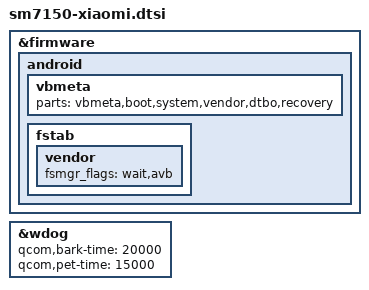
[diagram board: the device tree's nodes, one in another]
&firmware {
  android {
    vbmeta {
      parts = "vbmeta,boot,system,vendor,dtbo,recovery";
    };
    fstab {
      vendor {
          fsmgr_flags = "wait,avb";
      };
    };
  };
};

&wdog {
    qcom,bark-time = <20000>;
    qcom,pet-time = <15000>;
};
